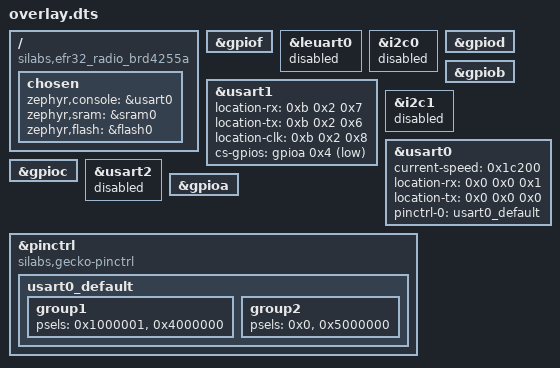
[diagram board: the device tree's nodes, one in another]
/ {
	compatible = "silabs,efr32_radio_brd4255a", "silabs,efr32fg13p";
	chosen {
		zephyr,console = &usart0;
		zephyr,sram = &sram0;
		zephyr,flash = &flash0;
	};
};
&gpiof{
	status = "okay";
};
&leuart0{
	status = "disabled";
};
&i2c0{
	status = "disabled";
};
&gpiod{
	status = "okay";
};
&gpiob{
	status = "okay";
};
&usart1{
	status = "okay";
	#address-cells = < 0x1 >;
	#size-cells = < 0x0 >;
	location-rx = < 0xb 0x2 0x7 >;
	location-tx = < 0xb 0x2 0x6 >;
	location-clk = < 0xb 0x2 0x8 >;
	cs-gpios = < &gpioa 0x4 0x1 >;
};
&i2c1{
	status = "disabled";
};
&usart0{
	status = "okay";
	current-speed = < 0x1c200 >;
	location-rx = < 0x0 0x0 0x1 >;
	location-tx = < 0x0 0x0 0x0 >;
	pinctrl-0 = < &usart0_default >;
	pinctrl-names = "default";
};
&gpioc{
	status = "okay";
};
&usart2{
	status = "disabled";
};
&gpioa{
	status = "okay";
};
&pinctrl{
	compatible = "silabs,gecko-pinctrl";
	usart0_default: usart0_default {
		group1 {
			psels = < 0x1000001 >, < 0x4000000 >;
		};
		group2 {
			psels = < 0x0 >, < 0x5000000 >;
		};
	};
};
